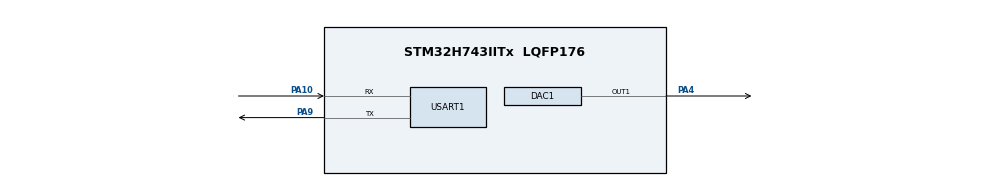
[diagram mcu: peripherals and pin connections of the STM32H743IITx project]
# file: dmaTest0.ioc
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CORTEX_M7.CPU_DCache=Disabled
CORTEX_M7.CPU_ICache=Disabled
DAC1.DAC_Channel-DAC_OUT1=DAC_CHANNEL_1
DAC1.DAC_Trigger-DAC_OUT1=DAC_TRIGGER_T1_TRGO
DAC1.WaveGeneration-DAC_OUT1=DISABLE
Dma.DAC1_CH1.0.Direction=DMA_MEMORY_TO_PERIPH
Dma.DAC1_CH1.0.EventEnable=DISABLE
Dma.DAC1_CH1.0.FIFOMode=DMA_FIFOMODE_DISABLE
Dma.DAC1_CH1.0.Instance=DMA1_Stream0
Dma.DAC1_CH1.0.MemDataAlignment=DMA_MDATAALIGN_HALFWORD
Dma.DAC1_CH1.0.MemInc=DMA_MINC_ENABLE
Dma.DAC1_CH1.0.Mode=DMA_CIRCULAR
Dma.DAC1_CH1.0.PeriphDataAlignment=DMA_PDATAALIGN_HALFWORD
Dma.DAC1_CH1.0.PeriphInc=DMA_PINC_DISABLE
Dma.DAC1_CH1.0.Polarity=HAL_DMAMUX_REQ_GEN_RISING
Dma.DAC1_CH1.0.Priority=DMA_PRIORITY_LOW
Dma.DAC1_CH1.0.RequestNumber=1
Dma.DAC1_CH1.0.SignalID=NONE
Dma.DAC1_CH1.0.SyncEnable=ENABLE
Dma.DAC1_CH1.0.SyncPolarity=HAL_DMAMUX_SYNC_RISING
Dma.DAC1_CH1.0.SyncRequestNumber=1
Dma.DAC1_CH1.0.SyncSignalID=HAL_DMAMUX1_SYNC_LPTIM1_OUT
Dma.Request0=DAC1_CH1
LPTIM1.ClockPrescaler=LPTIM_PRESCALER_DIV1
Mcu.Family=STM32H7
Mcu.Name=STM32H743IITx
Mcu.Package=LQFP176
NVIC.DMA1_Stream0_IRQn=true\:0\:0\:false\:false\:true\:false\:true\:true
NVIC.DMAMUX1_OVR_IRQn=true\:0\:0\:false\:false\:true\:false\:true\:true
NVIC.PriorityGroup=NVIC_PRIORITYGROUP_4
NVIC.TIM1_TRG_COM_IRQn=true\:0\:0\:false\:false\:true\:true\:true\:true
NVIC.TIM1_UP_IRQn=true\:0\:0\:false\:false\:true\:true\:true\:true
NVIC.USART1_IRQn=true\:0\:0\:false\:false\:true\:true\:true\:true
PA10.Mode=Asynchronous
PA10.Signal=USART1_RX
PA13\ (JTMS/SWDIO).Mode=Serial_Wire
PA13\ (JTMS/SWDIO).Signal=DEBUG_JTMS-SWDIO
PA14\ (JTCK/SWCLK).Mode=Serial_Wire
PA14\ (JTCK/SWCLK).Signal=DEBUG_JTCK-SWCLK
PA4.Signal=COMP_DAC11_group
PA9.Mode=Asynchronous
PA9.Signal=USART1_TX
PH0-OSC_IN\ (PH0).Mode=HSE-External-Oscillator
PH0-OSC_IN\ (PH0).Signal=RCC_OSC_IN
PH1-OSC_OUT\ (PH1).Mode=HSE-External-Oscillator
PH1-OSC_OUT\ (PH1).Signal=RCC_OSC_OUT
ProjectManager.HeapSize=0x200
ProjectManager.StackSize=0x400
ProjectManager.TargetToolchain=MDK-ARM V5.32
RCC.ADCFreq_Value=7031250
RCC.APB1Freq_Value=120000000
RCC.APB2Freq_Value=120000000
RCC.APB3Freq_Value=120000000
RCC.APB4Freq_Value=120000000
RCC.CortexFreq_Value=480000000
RCC.D1PPRE=RCC_APB3_DIV2
RCC.D2PPRE1=RCC_APB1_DIV2
RCC.D2PPRE2=RCC_APB2_DIV2
RCC.D3PPRE=RCC_APB4_DIV2
RCC.DIVM1=3
RCC.DIVM2=4
RCC.DIVN1=240
RCC.DIVN2=9
RCC.DIVP2=4
RCC.EnbaleCSS=true
RCC.HCLKFreq_Value=240000000
RCC.HPRE=RCC_HCLK_DIV2
RCC.HSE_VALUE=12000000
RCC.PLL2FRACN=3072
RCC.PLLFRACN=0
RCC.PLLSourceVirtual=RCC_PLLSOURCE_HSE
RCC.SYSCLKFreq_VALUE=480000000
RCC.SYSCLKSource=RCC_SYSCLKSOURCE_PLLCLK
RCC.USBFreq_Value=480000000
SH.COMP_DAC11_group.0=DAC1_OUT1,DAC_OUT1
TIM1.AutoReloadPreload=TIM_AUTORELOAD_PRELOAD_ENABLE
TIM1.Period=79
TIM1.Prescaler=7
TIM1.TIM_MasterOutputTrigger=TIM_TRGO_UPDATE
TIM1.TIM_MasterSlaveMode=TIM_MASTERSLAVEMODE_ENABLE
TIM2.AutoReloadPreload=TIM_AUTORELOAD_PRELOAD_ENABLE
TIM2.Period=1
TIM2.Prescaler=3
USART1.VirtualMode-Asynchronous=VM_ASYNC
VP_LPTIM1_VS_LPTIM_counterModeInternalClock.Mode=Counts__internal_clock_event_00
VP_TIM1_VS_ClockSourceINT.Mode=Internal
VP_TIM2_VS_ClockSourceITR.Mode=TriggerSource_ITR0
VP_TIM2_VS_ControllerModeClock.Mode=Clock Mode
board=custom

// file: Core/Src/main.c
/* USER CODE BEGIN Header */
/**
  ******************************************************************************
  * @file           : main.c
  * @brief          : Main program body
  ******************************************************************************
  * @attention
  *
  * Copyright (c) 2023 STMicroelectronics.
  * All rights reserved.
  *
  * This software is licensed under terms that can be found in the LICENSE file
  * in the root directory of this software component.
  * If no LICENSE file comes with this software, it is provided AS-IS.
  *
  ******************************************************************************
  */
/* USER CODE END Header */
#include "main.h"
#include "dac.h"
#include "dma.h"
#include "lptim.h"
#include "tim.h"
#include "usart.h"
#include "gpio.h"

/* USER CODE BEGIN Includes */
#include <stdio.h>
/* USER CODE END Includes */

/* USER CODE BEGIN PV */
uint16_t val = 0;
/* USER CODE END PV */

void SystemClock_Config(void);

/* USER CODE BEGIN 0 */
int fputc(int ch, FILE *f) {
  //HAL_UART_Transmit(&huart1, (const uint8_t *)&ch, 1, 0xFFFF);
  return ch;
}

void HAL_TIM_PeriodElapsedCallback(TIM_HandleTypeDef *htim) {
	if(htim->Instance == TIM1) {
		//val = __HAL_TIM_GetCounter(&htim2) ? 0 : 4095;
		//HAL_DAC_Start_DMA(&hdac1, DAC_CHANNEL_1, &val, 1, DAC_ALIGN_12B_R);
		//HAL_DAC_SetValue(&hdac1, DAC_CHANNEL_1, DAC_ALIGN_12B_R, val);
	}
}
/* USER CODE END 0 */

int main(void)
{

  /* MCU Configuration--------------------------------------------------------*/

  /* Reset of all peripherals, Initializes the Flash interface and the Systick. */
  HAL_Init();

  /* Configure the system clock */
  SystemClock_Config();

  /* Initialize all configured peripherals */
  MX_GPIO_Init();
  MX_DMA_Init();
  MX_DAC1_Init();
  MX_TIM2_Init();
  MX_TIM1_Init();
  MX_USART1_UART_Init();
  MX_LPTIM1_Init();
  /* USER CODE BEGIN 2 */

	// HAL_LPTIM_Counter_Start(&hlptim1, 0);
	// HAL_TIM_Base_Start(&htim2);
	//HAL_TIM_Base_Start_IT(&htim1);
	//HAL_DAC_Start_DMA(&hdac1, DAC_CHANNEL_1, &val, 1, DAC_ALIGN_12B_R);
	//printf("Testing testing?");
  //HAL_UART_Init(&huart1);
  //HAL_UART_Transmit(&huart1, (uint8_t *)"Testing testing\n", 17, 0xFFFF);
	//HAL_DAC_Start(&hdac1, DAC_CHANNEL_1);

  /* USER CODE END 2 */

  /* Infinite loop */
  /* USER CODE BEGIN WHILE */
  while (1)
  {
	printf("Testing testing\n");
    /* USER CODE END WHILE */

  }
}

void SystemClock_Config(void)
{
  RCC_OscInitTypeDef RCC_OscInitStruct = {0};
  RCC_ClkInitTypeDef RCC_ClkInitStruct = {0};

  /** Supply configuration update enable
  */
  HAL_PWREx_ConfigSupply(PWR_LDO_SUPPLY);

  /** Configure the main internal regulator output voltage
  */
  __HAL_PWR_VOLTAGESCALING_CONFIG(PWR_REGULATOR_VOLTAGE_SCALE1);

  while(!__HAL_PWR_GET_FLAG(PWR_FLAG_VOSRDY)) {}

  __HAL_RCC_SYSCFG_CLK_ENABLE();
  __HAL_PWR_VOLTAGESCALING_CONFIG(PWR_REGULATOR_VOLTAGE_SCALE0);

  while(!__HAL_PWR_GET_FLAG(PWR_FLAG_VOSRDY)) {}

  /** Initializes the RCC Oscillators according to the specified parameters
  * in the RCC_OscInitTypeDef structure.
  */
  RCC_OscInitStruct.OscillatorType = RCC_OSCILLATORTYPE_HSE;
  RCC_OscInitStruct.HSEState = RCC_HSE_ON;
  RCC_OscInitStruct.PLL.PLLState = RCC_PLL_ON;
  RCC_OscInitStruct.PLL.PLLSource = RCC_PLLSOURCE_HSE;
  RCC_OscInitStruct.PLL.PLLM = 3;
  RCC_OscInitStruct.PLL.PLLN = 240;
  RCC_OscInitStruct.PLL.PLLP = 2;
  RCC_OscInitStruct.PLL.PLLQ = 2;
  RCC_OscInitStruct.PLL.PLLR = 2;
  RCC_OscInitStruct.PLL.PLLRGE = RCC_PLL1VCIRANGE_2;
  RCC_OscInitStruct.PLL.PLLVCOSEL = RCC_PLL1VCOWIDE;
  RCC_OscInitStruct.PLL.PLLFRACN = 0;
  if (HAL_RCC_OscConfig(&RCC_OscInitStruct) != HAL_OK)
  {
    Error_Handler();
  }

  /** Initializes the CPU, AHB and APB buses clocks
  */
  RCC_ClkInitStruct.ClockType = RCC_CLOCKTYPE_HCLK|RCC_CLOCKTYPE_SYSCLK
                              |RCC_CLOCKTYPE_PCLK1|RCC_CLOCKTYPE_PCLK2
                              |RCC_CLOCKTYPE_D3PCLK1|RCC_CLOCKTYPE_D1PCLK1;
  RCC_ClkInitStruct.SYSCLKSource = RCC_SYSCLKSOURCE_PLLCLK;
  RCC_ClkInitStruct.SYSCLKDivider = RCC_SYSCLK_DIV1;
  RCC_ClkInitStruct.AHBCLKDivider = RCC_HCLK_DIV2;
  RCC_ClkInitStruct.APB3CLKDivider = RCC_APB3_DIV2;
  RCC_ClkInitStruct.APB1CLKDivider = RCC_APB1_DIV2;
  RCC_ClkInitStruct.APB2CLKDivider = RCC_APB2_DIV2;
  RCC_ClkInitStruct.APB4CLKDivider = RCC_APB4_DIV2;

  if (HAL_RCC_ClockConfig(&RCC_ClkInitStruct, FLASH_LATENCY_4) != HAL_OK)
  {
    Error_Handler();
  }

  /** Enables the Clock Security System
  */
  HAL_RCC_EnableCSS();
}

void Error_Handler(void)
{
  __disable_irq();
  while (1)
  {
  }
}
